# A31G11x register map
Vendor: VENDOR ABOV Semiconductor Co., Ltd.; Series: A31G11x; File version: 1.0
ARM 32-bit Cortex-M0+ Microcontroller based device, CPU clock up to 40MHz, etc.
CPU: CM0+ r0p1, little endian, no MPU, no FPU, VTOR, 2 interrupt priority bits
Registers are 32-bit, read-write, reset 0x0 unless marked. A register's access mark holds for its fields unless they carry their own. Offsets are from the block's base; lines under a group give offsets from that group; [hi:lo] are bit positions; {n}, {i} and the like mark numbered series; 'fields as' and 'values as' point back to an identical list; <NAME> marks a mode.

## Memory map
0x1FFFF000 COA0 size 0x100 — Configuration Option Area Page 0: System Related Trimming Value
0x1FFFF200 COA1 size 0x100 — Configuration Option Area Page 1: User Option
0x1FFFF400 COA2 size 0x100 — Configuration Option Area Page 2: User Data Area 0
0x1FFFF600 COA3 size 0x100 — Configuration Option Area Page 3: User Data Area 1
0x30000000 PA size 0x100 — Port Control Unit & GPIO Port A
0x30000100 PB size 0x100 — Port Control Unit & GPIO Port B
0x30000200 PC size 0x100 — Port Control Unit & GPIO Port C
0x30000300 PD size 0x100 — Port Control Unit & GPIO Port D
0x30000400 PE size 0x100 — Port Control Unit & GPIO Port E
0x30000500 PF size 0x100 — Port Control Unit & GPIO Port F
0x30001000 CRC size 0x100 — Cyclic Redundancy Check and Checksum
0x40001000 INTC size 0x500 — Interrupt Controller
0x40001800 SCUCG size 0x100 — System Control Unit: Clock Generation
0x40001A00 WDT size 0x100 — Watch-Dog Timer
0x40001B00 FMC size 0x200 — Flash Memory Controller
0x40002000 WT size 0x100 — Watch Timer
0x40002100 TIMER10 size 0x100 — Timer/Counter 10
0x40002200 TIMER11 size 0x100 — Timer/Counter 11
0x40002300 TIMER12 size 0x100 — Timer/Counter 12
0x40002400 TIMER30 size 0x100 — Timer/Counter 30
0x40002500 TIMER20 size 0x100 — Timer/Counter 20
0x40002600 TIMER21 size 0x100 — Timer/Counter 21
0x40003000 ADC size 0x100 — 12 Bit A/D Converter
0x40003800 USART10 size 0x100 — USART 10 (USART + SPI)
0x40003900 USART11 size 0x100 — USART 11 (USART + SPI)
0x40004000 UART0 size 0x100
0x40004100 UART1 size 0x100
0x40004800 I2C0 size 0x100
0x40004900 I2C1 size 0x100
0x40005000 LCD size 0x100 — LCD Driver
0x40005100 SCULV size 0x100 — System Control Unit: LVI and LVR
0x4000F000 SCUCC size 0x100 — System Control Unit: Chip Configuration
0x50000000 Pn size 0x100 — Port Control Unit & GPIO Port n
0x51000000 TIMER1n size 0x100 — Timer/Counter 1n
0x52000000 TIMER2n size 0x100 — Timer/Counter 2n
0x53000000 TIMER3n size 0x100 — Timer/Counter 3n
0x54000000 USART1n size 0x100 — USART 1n (USART + SPI)
0x55000000 UARTn size 0x100
0x56000000 I2Cn size 0x100

## Interrupts
0 LVI (SCULV) — LVI Interrupt
1 WUT (SCUCC) — WUT Interrupt
2 WDT — WDT Interrupt
3 EINT0 (INTC) — EINT0 Interrupt
4 EINT1 (INTC) — EINT1 Interrupt
5 EINT2 (INTC) — EINT2 Interrupt
6 EINT3 (INTC) — EINT3 Interrupt
7 TIMER10 — TIMER10 Interrupt
8 TIMER11 — TIMER11 Interrupt
9 TIMER12 — TIMER12 Interrupt
10 I2C0 — I2C0 Interrupt
11 USART10 — USART10 Interrupt
12 WT — WT Interrupt
13 TIMER30 — TIMER30 Interrupt
14 I2C1 — I2C1 Interrupt
15 TIMER20 — TIMER20 Interrupt
16 TIMER21 — TIMER21 Interrupt
17 USART11 — USART11 Interrupt
18 ADC — ADC Interrupt
19 UART0 — UART0 Interrupt
20 UART1 — UART1 Interrupt

## INTC — Interrupt Controller
Base 0x40001000
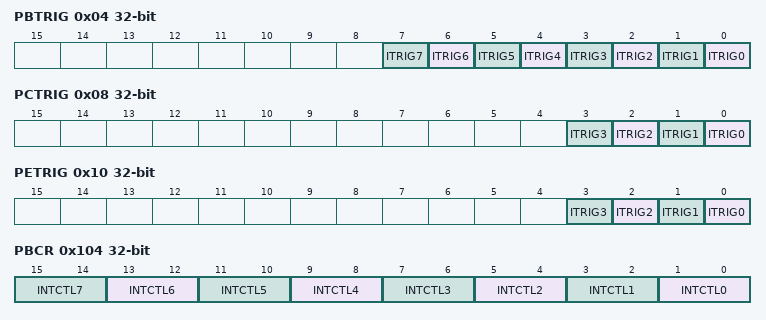
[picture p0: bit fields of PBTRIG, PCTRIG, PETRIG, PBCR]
0x04 PBTRIG — Port B Interrupt Trigger Selection Register
  [all] fields
    0=Edge trigger interrupt; 1=Level trigger interrupt
  [n] ITRIG{n} (n=0..7) — Port B Interrupt Trigger Selection {n}
0x08 PCTRIG — Port C Interrupt Trigger Selection Register
  [all] fields
    0=Edge trigger interrupt; 1=Level trigger interrupt
  [n] ITRIG{n} (n=0..3) — Port C Interrupt Trigger Selection {n}
0x10 PETRIG — Port E Interrupt Trigger Selection Register
  [all] fields
    0=Edge trigger interrupt; 1=Level trigger interrupt
  [n] ITRIG{n} (n=0..3) — Port E Interrupt Trigger Selection {n}
0x104 PBCR — Port B Interrupt Control Register
  [all] fields
    0=Disable external interrupt; 1=FallingEdgeLowLevel (Interrupt on falling edge or on low level); 2=RisingEdgeHighLevel (Interrupt on rising edge or on high level); 3=BothEdgeNoLevel (Interrupt on both falling and rising edge, No level interrupt)
  [2n+1:2n] INTCTL{n} (n=0..7) — Port B Interrupt Control {n}
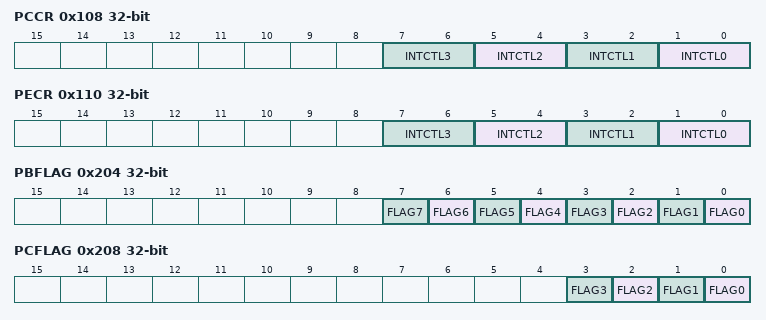
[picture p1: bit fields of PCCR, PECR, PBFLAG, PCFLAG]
0x108 PCCR — Port C Interrupt Control Register
  [all] fields
    values as the fields of PBCR
  [2n+1:2n] INTCTL{n} (n=0..3) — Port C Interrupt Control {n}
0x110 PECR — Port E Interrupt Control Register
  [all] fields
    values as the fields of PBCR
  [2n+1:2n] INTCTL{n} (n=0..3) — Port E Interrupt Control {n}
0x204 PBFLAG — Port B Interrupt Flag Register
  [all] fields
    0=No request occurred; 1=Request occurred
  [n] FLAG{n} (n=0..7) — Port B Interrupt Flag {n}
0x208 PCFLAG — Port C Interrupt Flag Register
  [all] fields
    0=No request occurred; 1=Request occurred
  [n] FLAG{n} (n=0..3) — Port C Interrupt Flag {n}
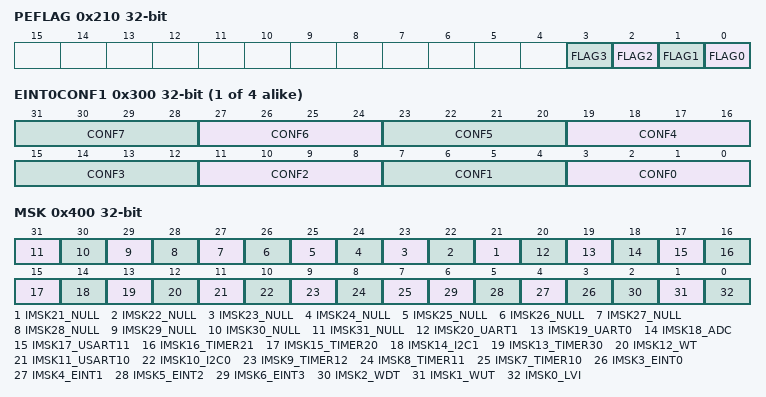
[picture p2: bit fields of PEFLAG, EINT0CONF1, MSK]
0x210 PEFLAG — Port E Interrupt Flag Register
  [all] fields
    0=No request occurred; 1=Request occurred
  [n] FLAG{n} (n=0..3) — Port E Interrupt Flag {n}
{0x300+4i} EINT{i}CONF1 (i=0..3) — External Interrupt {i} Configuration Register 1
  [all] fields
    0=PA (Select PA.); 1=PB (Select PB.); 2=PC (Select PC.); 3=PD (Select PD.); 4=PE (Select PE.); 5=PF (Select PF.)
  [4n+3:4n] CONF{n} (n=0..7) — External Interrupt {i} Configuration {n}
0x400 MSK — Interrupt Source Mask Register
  [all] fields
    0=Mask Interrupt Source; 1=Unmask Interrupt Source
  [n] IMSK{n}_NULL (n=21..31) — Interrupt Source Mask {n} (RSVD)
  [20] IMSK20_UART1 — Interrupt Source Mask 20 (UART1)
  [19] IMSK19_UART0 — Interrupt Source Mask 19 (UART0)
  [18] IMSK18_ADC — Interrupt Source Mask 18 (ADC)
  [17] IMSK17_USART11 — Interrupt Source Mask 17 (USART11)
  [16] IMSK16_TIMER21 — Interrupt Source Mask 16 (TIMER21)
  [15] IMSK15_TIMER20 — Interrupt Source Mask 15 (TIMER20)
  [14] IMSK14_I2C1 — Interrupt Source Mask 14 (I2C1)
  [13] IMSK13_TIMER30 — Interrupt Source Mask 13 (TIMER30)
  [12] IMSK12_WT — Interrupt Source Mask 12 (WT)
  [11] IMSK11_USART10 — Interrupt Source Mask 11 (USART10)
  [10] IMSK10_I2C0 — Interrupt Source Mask 10 (I2C0)
  [9] IMSK9_TIMER12 — Interrupt Source Mask 9 (TIMER12)
  [8] IMSK8_TIMER11 — Interrupt Source Mask 8 (TIMER11)
  [7] IMSK7_TIMER10 — Interrupt Source Mask 7 (TIMER10)
  [n] IMSK{n}_EINT{n-3} (n=3..6) — Interrupt Source Mask {n} (EINT{n-3})
  [2] IMSK2_WDT — Interrupt Source Mask 2 (WDT)
  [1] IMSK1_WUT — Interrupt Source Mask 1 (WUT)
  [0] IMSK0_LVI — Interrupt Source Mask 0 (LVI)

## Licence text in the file
ARM Limited (ARM) is supplying this software for use with Cortex-M processor based microcontroller, but can be equally used for other suitable processor architectures. This file can be freely distributed. Modifications to this file shall be clearly marked. . THIS SOFTWARE IS PROVIDED "AS IS". NO WARRANTIES, WHETHER EXPRESS, IMPLIED. OR STATUTORY, INCLUDING, BUT NOT LIMITED TO, IMPLIED WARRANTIES OF. MERCHANTABILITY AND FITNESS FOR A PARTICULAR PURPOSE APPLY TO THIS SOFTWARE. ARM SHALL NOT, IN ANY CIRCUMSTANCES, BE LIABLE FOR SPECIAL, INCIDENTAL, OR. CONSEQUENTIAL DAMAGES, FOR ANY REASON WHATSOEVER.

## Notices in the file
Copyright (C) 2012 ARM Limited. All rights reserved.
Purpose: System Viewer Description (SVD) Example (Schema Version 1.1)
This is a description of a none-existent and incomplete device
for demonstration purposes only.
Redistribution and use in source and binary forms, with or without
modification, are permitted provided that the following conditions are met:
- Redistributions of source code must retain the above copyright
notice, this list of conditions and the following disclaimer.
- Redistributions in binary form must reproduce the above copyright
notice, this list of conditions and the following disclaimer in the
documentation and/or other materials provided with the distribution.
- Neither the name of ARM nor the names of its contributors may be used
to endorse or promote products derived from this software without
specific prior written permission.
THIS SOFTWARE IS PROVIDED BY THE COPYRIGHT HOLDERS AND CONTRIBUTORS "AS IS"
AND ANY EXPRESS OR IMPLIED WARRANTIES, INCLUDING, BUT NOT LIMITED TO, THE
ARE DISCLAIMED. IN NO EVENT SHALL COPYRIGHT HOLDERS AND CONTRIBUTORS BE
LIABLE FOR ANY DIRECT, INDIRECT, INCIDENTAL, SPECIAL, EXEMPLARY, OR
CONSEQUENTIAL DAMAGES (INCLUDING, BUT NOT LIMITED TO, PROCUREMENT OF
SUBSTITUTE GOODS OR SERVICES; LOSS OF USE, DATA, OR PROFITS; OR BUSINESS
INTERRUPTION) HOWEVER CAUSED AND ON ANY THEORY OF LIABILITY, WHETHER IN
CONTRACT, STRICT LIABILITY, OR TORT (INCLUDING NEGLIGENCE OR OTHERWISE)
ARISING IN ANY WAY OUT OF THE USE OF THIS SOFTWARE, EVEN IF ADVISED OF THE
POSSIBILITY OF SUCH DAMAGE.
